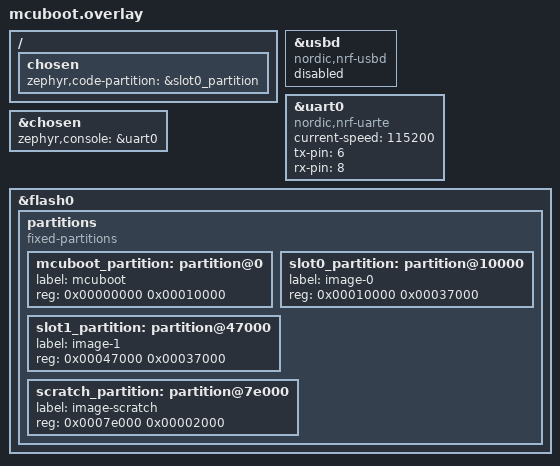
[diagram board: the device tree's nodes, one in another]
/ {
	chosen {
		zephyr,code-partition = &slot0_partition;
	};
};

/* CRITICAL: Disable USB in MCUboot - this prevents USB drivers from being linked */
/* This must be done in device tree to override board defaults */
&usbd {
	compatible = "nordic,nrf-usbd";
	status = "disabled";
};

/* Also disable any USB CDC ACM nodes that might exist */
/delete-node/ &cdc_acm_uart0;

/* Configure UART0 for MCUboot serial recovery */
&uart0 {
	compatible = "nordic,nrf-uarte";
	status = "okay";
	current-speed = <115200>;
	/* 
	 * Pin configuration - adjust these based on your hardware:
	 * For nRF52833, common UART pins are:
	 * - TX: P0.6 (default) or P0.20
	 * - RX: P0.8 (default) or P0.22
	 * If your board uses different pins, update these values
	 */
	tx-pin = <6>;   /* P0.6 */
	rx-pin = <8>;   /* P0.8 */
};

/* Set UART0 as console for MCUboot */
&chosen {
	zephyr,console = &uart0;
};

/* Flash partitions for MCUboot */
&flash0 {
	partitions {
		compatible = "fixed-partitions";
		#address-cells = <1>;
		#size-cells = <1>;

		mcuboot_partition: partition@0 {
			label = "mcuboot";
			reg = <0x00000000 0x00010000>;
		};

		slot0_partition: partition@10000 {
			label = "image-0";
			reg = <0x00010000 0x00037000>;
		};

		slot1_partition: partition@47000 {
			label = "image-1";
			reg = <0x00047000 0x00037000>;
		};

		scratch_partition: partition@7e000 {
			label = "image-scratch";
			reg = <0x0007e000 0x00002000>;
		};
	};
};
